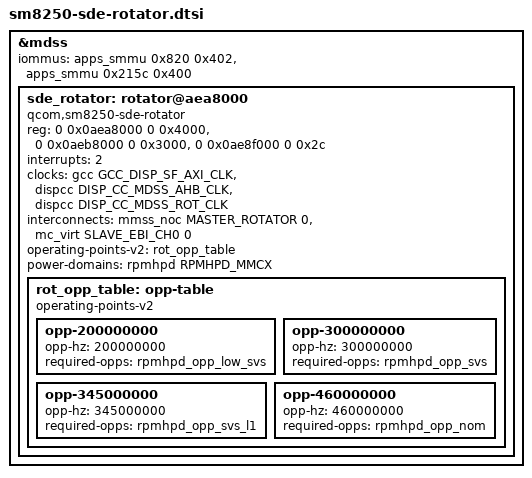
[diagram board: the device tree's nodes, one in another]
// SPDX-License-Identifier: BSD-3-Clause
/* offline SDE rotator */

&mdss {
	iommus = <&apps_smmu 0x820 0x402>,
		 <&apps_smmu 0x215c 0x400>;

	sde_rotator: rotator@aea8000 {
		compatible = "qcom,sm8250-sde-rotator";
		reg = <0 0x0aea8000 0 0x4000>,
		      <0 0x0aeb8000 0 0x3000>,
		      <0 0x0ae8f000 0 0x2c>;
		reg-names = "rot", "vbif", "sid";

		interrupts = <2>;

		clocks = <&gcc GCC_DISP_SF_AXI_CLK>,
			 <&dispcc DISP_CC_MDSS_AHB_CLK>,
			 <&dispcc DISP_CC_MDSS_ROT_CLK>;
		clock-names = "bus", "iface", "rot";

		interconnects = <&mmss_noc MASTER_ROTATOR 0 &mc_virt SLAVE_EBI_CH0 0>;
		interconnect-names = "mem";

		operating-points-v2 = <&rot_opp_table>;
		power-domains = <&rpmhpd RPMHPD_MMCX>;

		rot_opp_table: opp-table {
			compatible = "operating-points-v2";

			opp-200000000 {
				opp-hz = /bits/ 64 <200000000>;
				required-opps = <&rpmhpd_opp_low_svs>;
			};

			opp-300000000 {
				opp-hz = /bits/ 64 <300000000>;
				required-opps = <&rpmhpd_opp_svs>;
			};

			opp-345000000 {
				opp-hz = /bits/ 64 <345000000>;
				required-opps = <&rpmhpd_opp_svs_l1>;
			};

			opp-460000000 {
				opp-hz = /bits/ 64 <460000000>;
				required-opps = <&rpmhpd_opp_nom>;
			};
		};
	};
};
